# G32F031 register map
File version: 1.0
CPU: CM0PLUS r0p1, little endian, no MPU, no FPU, 2 interrupt priority bits
Registers are 32-bit, read-write, reset 0x0 unless marked. A register's access mark holds for its fields unless they carry their own. Offsets are from the block's base; [hi:lo] are bit positions.

## WWDT — Window watchdog
Base 0x40002C00
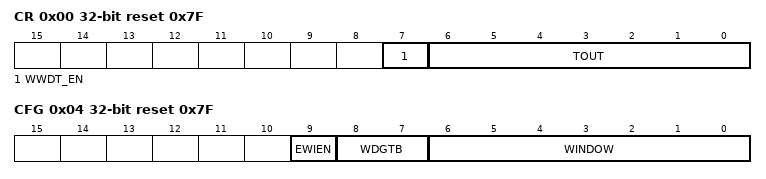
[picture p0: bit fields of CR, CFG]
0x00 CR reset 0x7F — Control register
  [7] WWDT_EN — Activation bit
  [6:0] TOUT — 7-bit counter (MSB to LSB)
0x04 CFG reset 0x7F — Configuration register
  [9] EWIEN — Early wakeup interrupt
  [8:7] WDGTB — Timer Base Prescaler Factor Configure
  [6:0] WINDOW — 7-bit window value
0x08 SR — Status register
  [0] EWIF — Early wakeup interrupt flag

## SPI — Serial peripheral interface
Base 0x40003000
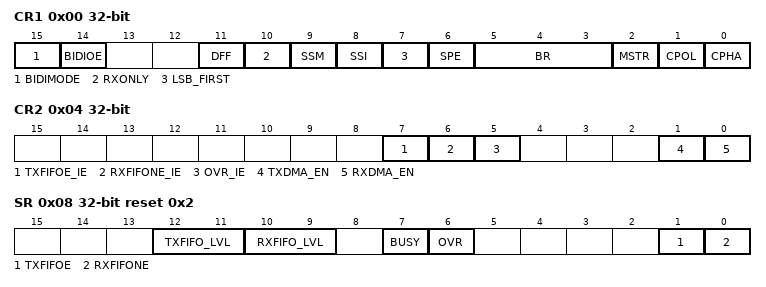
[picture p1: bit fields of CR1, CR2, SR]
0x00 CR1 — control register 1
  [15] BIDIMODE — Bidirectional data mode enable
  [14] BIDIOE — Output enable in bidirectional mode
  [11] DFF — Data frame format
  [10] RXONLY — Receive only
  [9] SSM — Software slave management
  [8] SSI — Internal slave select
  [7] LSB_FIRST — Frame format
  [6] SPE — SPI enable
  [5:3] BR — Baud rate control
  [2] MSTR — Master selection
  [1] CPOL — Clock polarity
  [0] CPHA — Clock phase
0x04 CR2 — control register 2
  [7] TXFIFOE_IE — Tx buffer empty interrupt enable
  [6] RXFIFONE_IE — RX buffer not empty interrupt enable
  [5] OVR_IE — Error interrupt enable
  [1] TXDMA_EN — Tx buffer DMA enable
  [0] RXDMA_EN — Rx buffer DMA enable
0x08 SR ro reset 0x2 — status register
  [12:11] TXFIFO_LVL — Transmit FIFO Threshold
  [10:9] RXFIFO_LVL — Receive FIFO Threshold
  [7] BUSY — Busy flag
  [6] OVR — Overrun flag
  [1] TXFIFOE — Transmit buffer empty
  [0] RXFIFONE — Receive buffer not empty
0x0C DR — data register
  [15:0] DR — Data register

## USART — Universal asynchronous receiver transmitter
Base 0x40003800
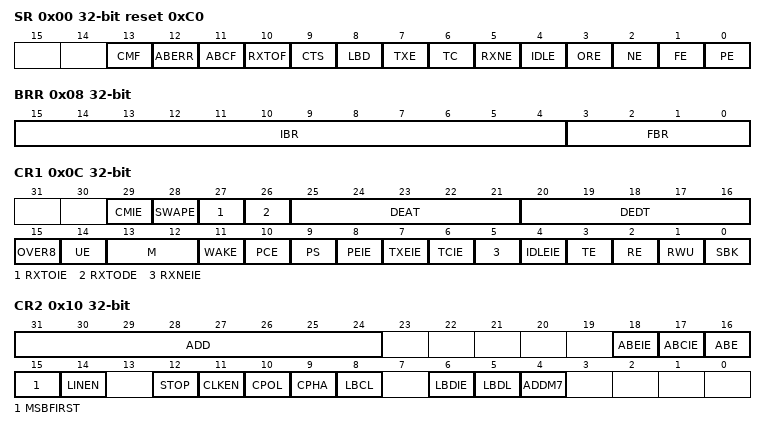
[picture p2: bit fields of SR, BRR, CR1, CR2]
0x00 SR access per field reset 0xC0
  [13] CMF rw — character matching flag
  [12] ABERR rw — Auto BR error flag
  [11] ABCF rw — Auto BR complete flag
  [10] RXTOF rw — RX timeout flag
  [9] CTS rw — CTS flag
  [8] LBD rw — LIN break detection flag
  [7] TXE ro — Transmit data register empty
  [6] TC ro — Transmission complete
  [5] RXNE ro — Read data register not empty
  [4] IDLE ro — IDLE line detected
  [3] ORE ro — Overrun error
  [2] NE ro — Noise error flag
  [1] FE ro — Framing error
  [0] PE ro — Parity error
0x04 DR
  [8:0] DR — Data value
0x08 BRR
  [15:4] IBR — Integer baud rate
  [3:0] FBR — Fractional baud rate
0x0C CR1
  [29] CMIE — Character match interrupt enable
  [28] SWAPE — Swap TX/RX Pins Function Enable
  [27] RXTOIE — Receiver Timeout Interrupt Enable
  [26] RXTODE — Receive Timeout Detection Function Enable
  [25:21] DEAT — Driver enable assertion time
  [20:16] DEDT — Driver enable deassertion time
  [15] OVER8 — Oversampling mode configure
  [14] UE — USART enable
  [13:12] M — Word length
  [11] WAKE — Wakeup method
  [10] PCE — Parity control enable
  [9] PS — Parity selection
  [8] PEIE — PE interrupt enable
  [7] TXEIE — TXE interrupt enable
  [6] TCIE — Transmission complete interrupt enable
  [5] RXNEIE — RXNE interrupt enable
  [4] IDLEIE — IDLE interrupt enable
  [3] TE — Transmitter enable
  [2] RE — Receiver enable
  [1] RWU — Receiver wakeup
  [0] SBK — Send break
0x10 CR2
  [31:24] ADD — Node address
  [18] ABEIE — Auto baud error interrupt enable
  [17] ABCIE — Auto baud complete interrupt enable
  [16] ABE — Auto baud enable
  [15] MSBFIRST — Most significant bit first
  [14] LINEN — LIN mode enable
  [12] STOP — STOP bits
  [11] CLKEN — Clock enable
  [10] CPOL — Clock polarity
  [9] CPHA — Clock phase
  [8] LBCL — Last bit clock pulse
  [6] LBDIE — LIN break detection interrupt enable
  [5] LBDL — LIN break detection length
  [4] ADDM7 — Bit select of address measure
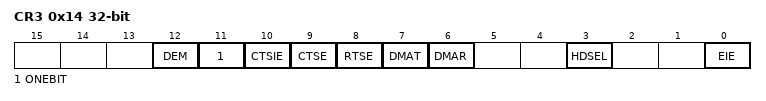
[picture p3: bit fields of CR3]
0x14 CR3
  [12] DEM — Driver enable mode
  [11] ONEBIT — Receive data sample mode
  [10] CTSIE — CTS interrupt enable
  [9] CTSE — CTS enable
  [8] RTSE — RTS enable
  [7] DMAT — DMA enable transmitter
  [6] DMAR — DMA enable receiver
  [3] HDSEL — Half-duplex selection
  [0] EIE — Error interrupt enable
0x1C RXTOR
  [23:0] RXTO — Receiver Timeout Value Setup
